# H616 register map
Vendor: Allwinner; Series: H616; File version: 0.1
CPU: other 0, little endian, MPU, no FPU, 0 interrupt priority bits
Registers are 32-bit, read-write, reset 0x0 unless marked. A register's access mark holds for its fields unless they carry their own. Offsets are from the block's base; [hi:lo] are bit positions; {n}, {i} and the like mark numbered series; 'fields as' and 'values as' point back to an identical list.

## CCU
Base 0x03001000
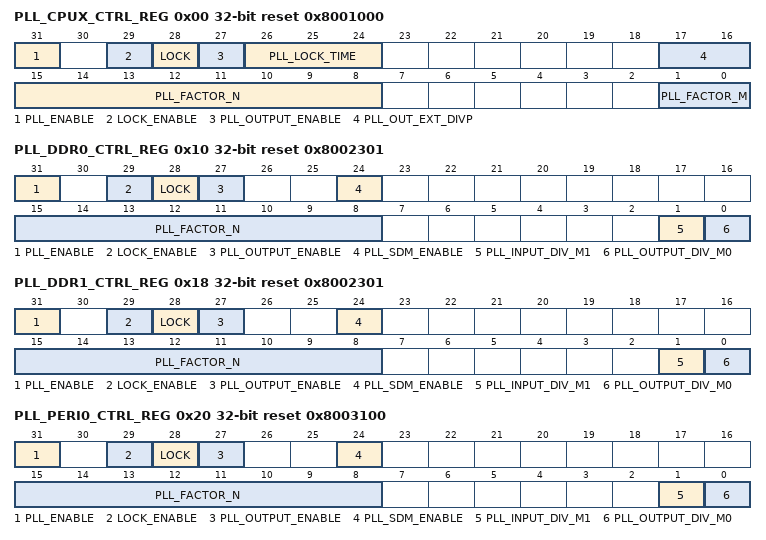
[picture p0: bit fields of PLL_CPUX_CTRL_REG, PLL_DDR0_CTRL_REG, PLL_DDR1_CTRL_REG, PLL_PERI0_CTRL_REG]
0x00 PLL_CPUX_CTRL_REG reset 0x8001000 — PLL_CPUX Control Register
  [31] PLL_ENABLE — 0: Disable 1: Enable PLL_CPUX=24 MHz*N/P The PLL_CPUX output frequency must be in the range from 200 MHz to 3 GHz. And the default value of PLL_CPUX is 408 MHz.
    0=Disable; 1=Enable PLL_CPUX=24 MHz*N/P The PLL_CPUX output frequency must be in the range from 200 MHz to 3 GHz. And the default value of PLL_CPUX is 408 MHz.
  [29] LOCK_ENABLE — Lock Enable 0: Disable 1: Enable
    0=Disable; 1=Enable
  [28] LOCK ro — 0:Unlocked 1: Locked (It indicates that the PLL has been stable.)
    1=Locked (It indicates that the PLL has been stable.)
  [27] PLL_OUTPUT_ENABLE — 0:Disable 1:Enable The bit is used to control the output enable of PLL.
  [26:24] PLL_LOCK_TIME — PLL lock time The bit indicates the step amplitude from one frequency to another.
  [17:16] PLL_OUT_EXT_DIVP — PLL Output External Divider P 00: 1 01: 2 10: 4 11: / When output clock is less than 288 MHz, clock frequency is output by dividing P.
    0=_1; 1=_2; 2=_4; 3=_slash_ (/ When output clock is less than 288 MHz, clock frequency is output by dividing P.)
  [15:8] PLL_FACTOR_N — PLL Factor N N= PLL_FACTOR_N +1 PLL_FACTOR_N is from 0 to 254. In application, PLL_FACTOR_N shall be more than or equal to 11.
  [1:0] PLL_FACTOR_M — PLL Factor M M = PLL_FACTOR_M + 1 PLL_FACTOR_M is from 0 to 3. Note: The bit is only for testing.
0x10 PLL_DDR0_CTRL_REG reset 0x8002301 — PLL_DDR0 Control Register
  [31] PLL_ENABLE — 0: Disable 1: Enable PLL_DDR= 24 MHz*N/M0/M1 The default value of PLL_DDR0 is 432 MHz.
    0=Disable; 1=Enable PLL_DDR= 24 MHz*N/M0/M1 The default value of PLL_DDR0 is 432 MHz
  [29] LOCK_ENABLE — Lock Enable 0: Disable 1: Enable
    0=Disable; 1=Enable
  [28] LOCK ro — 0: Unlocked 1: Locked (It indicates that the PLL has been stable.)
    0=Unlocked; 1=Locked (It indicates that the PLL has been stable.)
  [27] PLL_OUTPUT_ENABLE — 0:Disable 1:Enable The bit is used to control the output enable of PLL.
  [24] PLL_SDM_ENABLE — 0:Disable 1:Enable
  [15:8] PLL_FACTOR_N — PLL Factor N N= PLL_FACTOR_N +1 PLL_FACTOR_N is from 0 to 254. In application, PLL_FACTOR_N shall be more than or equal to 11.
  [1] PLL_INPUT_DIV_M1 — PLL Input Div M1. M1=PLL_INPUT_DIV_M1 + 1 PLL_INPUT_DIV_M1 is from 0 to 1.
  [0] PLL_OUTPUT_DIV_M0 — PLL Output Div M0. M0=PLL_OUTPUT_DIV_M0 + 1 PLL_OUTPUT_DIV_M0 is from 0 to 1.
0x18 PLL_DDR1_CTRL_REG reset 0x8002301 — PLL_DDR1 Control Register
  [31] PLL_ENABLE — 0: Disable 1: Enable PLL_DDR= 24 MHz*N/M0/M1 The default value of PLL_DDR1 is 432 MHz.
    0=Disable; 1=Enable PLL_DDR= 24 MHz*N/M0/M1 The default value of PLL_DDR1 is 432 MHz
  [29] LOCK_ENABLE — Lock Enable 0: Disable 1: Enable
    0=Disable; 1=Enable
  [28] LOCK ro — 0: Unlocked 1: Locked (It indicates that the PLL has been stable.)
    values as PLL_DDR0_CTRL_REG.LOCK
  [27] PLL_OUTPUT_ENABLE — 0:Disable 1:Enable The bit is used to control the output enable of PLL.
  [24] PLL_SDM_ENABLE — 0:Disable 1:Enable
  [15:8] PLL_FACTOR_N — PLL Factor N N= PLL_FACTOR_N +1 PLL_FACTOR_N is from 0 to 254. In application, PLL_FACTOR_N shall be more than or equal to 11.
  [1] PLL_INPUT_DIV_M1 — PLL Input Div M1. M1=PLL_INPUT_DIV_M1 + 1 PLL_INPUT_DIV_M1 is from 0 to 1.
  [0] PLL_OUTPUT_DIV_M0 — PLL Output Div M0. M0=PLL_OUTPUT_DIV_M0 + 1 PLL_OUTPUT_DIV_M0 is from 0 to 1.
0x20 PLL_PERI0_CTRL_REG reset 0x8003100 — PLL_PERI0 Control Register
  [31] PLL_ENABLE — 0: Disable 1: Enable PLL_PERI0(2X) = 24 MHz*N/M0/M1 PLL_PERI0(1X) = 24 MHz*N/M0/M1/2 The default value of PLL_PERI0(2X) is 1.2 GHz. It is not recommended to modify the value.
    0=Disable; 1=Enable PLL_PERI0(2X) = 24 MHz*N/M0/M1 PLL_PERI0(1X) = 24 MHz*N/M0/M1/2 The default value of PLL_PERI0(2X) is 1.2 GHz. It is not recommended to modify the value.
  [29] LOCK_ENABLE — Lock Enable 0: Disable 1: Enable
    0=Disable; 1=Enable
  [28] LOCK ro — 0: Unlocked 1: Locked (It indicates that the PLL has been stable.)
    values as PLL_DDR0_CTRL_REG.LOCK
  [27] PLL_OUTPUT_ENABLE — 0:Disable 1:Enable The bit is used to control the output enable of PLL.
  [24] PLL_SDM_ENABLE — 0: Disable 1: Enable
    0=Disable; 1=Enable
  [15:8] PLL_FACTOR_N — PLL Factor N N= PLL_FACTOR_N +1 PLL_FACTOR_N is from 0 to 254. In application, PLL_FACTOR_N shall be more than or equal to 11.
  [1] PLL_INPUT_DIV_M1 — PLL Input Div M1. M1=PLL_INPUT_DIV_M1 + 1 PLL_INPUT_DIV_M1 is from 0 to 1.
  [0] PLL_OUTPUT_DIV_M0 — PLL Output Div M0. M0=PLL_OUTPUT_DIV_M0 + 1 PLL_OUTPUT_DIV_M0 is from 0 to 1.
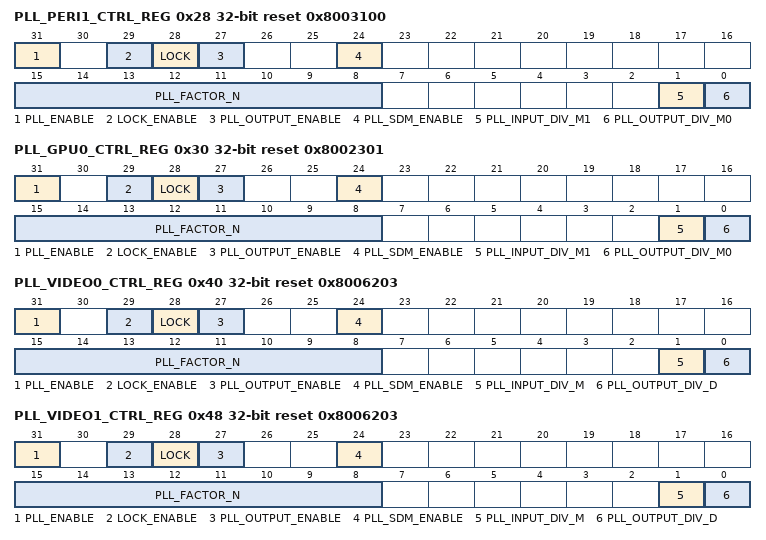
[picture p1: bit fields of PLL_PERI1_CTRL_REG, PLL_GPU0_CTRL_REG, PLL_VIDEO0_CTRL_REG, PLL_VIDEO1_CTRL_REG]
0x28 PLL_PERI1_CTRL_REG reset 0x8003100 — PLL_PERI1 Control Register
  [31] PLL_ENABLE — 0: Disable 1: Enable PLL_PERI1(2X) = 24 MHz*N/M0/M1. PLL_PERI1(1X) = 24 MHz*N/M0/M1/2. The default value of PLL_PERI1(2X) is 1.2 GHz. It is not recommended to modify the value.
    0=Disable; 1=Enable PLL_PERI1(2X) = 24 MHz*N/M0/M1. PLL_PERI1(1X) = 24 MHz*N/M0/M1/2. The default value of PLL_PERI1(2X) is 1.2 GHz. It is not recommended to modify the value.
  [29] LOCK_ENABLE — Lock Enable 0: Disable 1: Enable
    0=Disable; 1=Enable
  [28] LOCK ro — 0:Unlocked 1: Locked (It indicates that the PLL has been stable.)
    1=Locked (It indicates that the PLL has been stable.)
  [27] PLL_OUTPUT_ENABLE — 0:Disable 1:Enable The bit is used to control the output enable of PLL.
  [24] PLL_SDM_ENABLE — 0: Disable 1: Enable
    0=Disable; 1=Enable
  [15:8] PLL_FACTOR_N — PLL Factor N N= PLL_FACTOR_N +1 PLL_FACTOR_N is from 0 to 254. In application, PLL_FACTOR_N shall be more than or equal to 11.
  [1] PLL_INPUT_DIV_M1 — PLL Input Div M1 M1=PLL_INPUT_DIV_M1 + 1 PLL_INPUT_DIV_M1 is from 0 to 1.
  [0] PLL_OUTPUT_DIV_M0 — PLL Output Div M0 M0=PLL_OUTPUT_DIV_M0 + 1 PLL_OUTPUT_DIV_M0 is from 0 to 1.
0x30 PLL_GPU0_CTRL_REG reset 0x8002301 — PLL_GPU0 Control Register
  [31] PLL_ENABLE — 0: Disable 1: Enable PLL_GPU0 = 24 MHz*N/M0/M1. The default value of PLL_GPU0 is 432 MHz.
    0=Disable; 1=Enable PLL_GPU0 = 24 MHz*N/M0/M1. The default value of PLL_GPU0 is 432 MHz.
  [29] LOCK_ENABLE — Lock Enable 0: Disable 1: Enable
    0=Disable; 1=Enable
  [28] LOCK ro — 0:Unlocked 1: Locked (It indicates that the PLL has been stable.)
    1=Locked (It indicates that the PLL has been stable.)
  [27] PLL_OUTPUT_ENABLE — 0:Disable 1:Enable The bit is used to control the output enable of PLL.
  [24] PLL_SDM_ENABLE — 0: Disable 1: Enable
    0=Disable; 1=Enable
  [15:8] PLL_FACTOR_N — PLL Factor N. N= PLL_FACTOR_N +1 PLL_FACTOR_N is from 0 to 254. In application, PLL_FACTOR_N shall be more than or equal to 11.
  [1] PLL_INPUT_DIV_M1 — PLL Input Div M1. M1=PLL_INPUT_DIV_M1 + 1 PLL_INPUT_DIV_M1 is from 0 to 1.
  [0] PLL_OUTPUT_DIV_M0 — PLL Output Div M0. M0=PLL_OUTPUT_DIV_M0 + 1 PLL_OUTPUT_DIV_M0 is from 0 to 1.
0x40 PLL_VIDEO0_CTRL_REG reset 0x8006203 — PLL_VIDEO0 Control Register
  [31] PLL_ENABLE — 0: Disable 1: Enable For application, PLL_VIDEO0(4X)= 24 MHz*N/M. PLL_VIDEO0(1X)=24 MHz*N/M/4. The default value of PLL_VIDEO0(4X) is 1188 MHz.
    0=Disable; 1=Enable For application, PLL_VIDEO0(4X)= 24 MHz*N/M. PLL_VIDEO0(1X)=24 MHz*N/M/4. The default value of PLL_VIDEO0(4X) is 1188 MHz.
  [29] LOCK_ENABLE — Lock Enable 0: Disable 1: Enable
    0=Disable; 1=Enable
  [28] LOCK ro — 0:Unlocked 1: Locked (It indicates that the PLL has been stable.)
    1=Locked (It indicates that the PLL has been stable.)
  [27] PLL_OUTPUT_ENABLE — 0: Disable 1: Enable The bit is used to control the output enable of PLL.
    0=Disable; 1=Enable The bit is used to control the output enable of PLL
  [24] PLL_SDM_ENABLE — 0: Disable 1: Enable
    0=Disable; 1=Enable
  [15:8] PLL_FACTOR_N — PLL Factor N N= PLL_FACTOR_N +1 PLL_FACTOR_N is from 0 to 254. In application, PLL_FACTOR_N shall be more than or equal to 11.
  [1] PLL_INPUT_DIV_M — PLL Input Div M M1=PLL_INPUT_DIV_M + 1 PLL_INPUT_DIV_M is from 0 to 1.
  [0] PLL_OUTPUT_DIV_D — PLL Output Div D M0=PLL_OUTPUT_DIV_D + 1 PLL_OUTPUT_DIV_D is from 0 to 1. The bit is only for testing. For test, PLL_VIDEO0(4X) =24 MHz*N/M/D
0x48 PLL_VIDEO1_CTRL_REG reset 0x8006203 — PLL_VIDEO1 Control Register
  [31] PLL_ENABLE — 0: Disable 1: Enable For application, PLL_VIDEO1(4X)= 24 MHz*N/M. PLL_VIDEO1(1X)=24 MHz*N/M/4. The default value of PLL_VIDEO1(4X) is 1188 MHz.
    0=Disable; 1=Enable For application, PLL_VIDEO1(4X)= 24 MHz*N/M. PLL_VIDEO1(1X)=24 MHz*N/M/4. The default value of PLL_VIDEO1(4X) is 1188 MHz.
  [29] LOCK_ENABLE — Lock Enable 0: Disable 1: Enable
    0=Disable; 1=Enable
  [28] LOCK ro — 0: Unlocked 1: Locked (It indicates that the PLL has been stable.)
    values as PLL_DDR0_CTRL_REG.LOCK
  [27] PLL_OUTPUT_ENABLE — 0: Disable 1: Enable The bit is used to control the output enable of PLL.
    values as PLL_VIDEO0_CTRL_REG.PLL_OUTPUT_ENABLE
  [24] PLL_SDM_ENABLE — 0: Disable 1: Enable
    0=Disable; 1=Enable
  [15:8] PLL_FACTOR_N — PLL Factor N N= PLL_FACTOR_N +1 PLL_FACTOR_N is from 0 to 254. In application, PLL_FACTOR_N shall be more than or equal to 11.
  [1] PLL_INPUT_DIV_M — PLL Input Div M M1=PLL_INPUT_DIV_M + 1 PLL_INPUT_DIV_M is from 0 to 1.
  [0] PLL_OUTPUT_DIV_D — PLL Output Div D M0=PLL_OUTPUT_DIV_D + 1 PLL_OUTPUT_DIV_D is from 0 to 1. The bit is only for testing. For test, PLL_VIDEO0(4X) =24 MHz*N/M/D
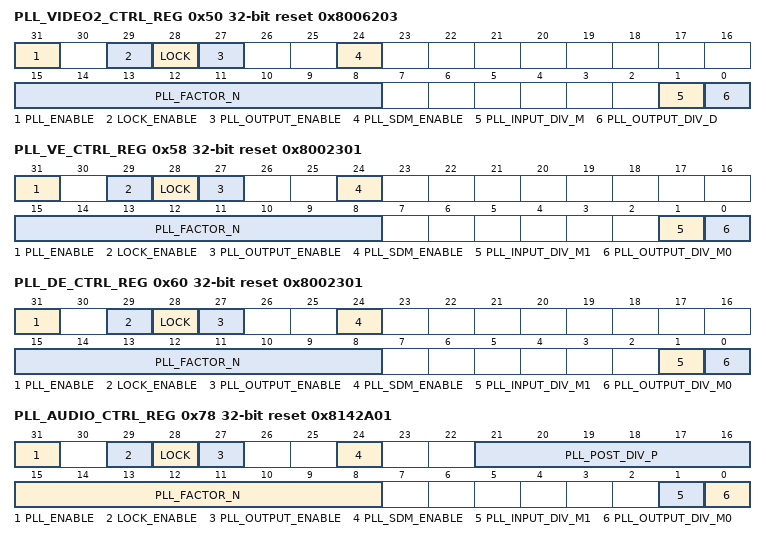
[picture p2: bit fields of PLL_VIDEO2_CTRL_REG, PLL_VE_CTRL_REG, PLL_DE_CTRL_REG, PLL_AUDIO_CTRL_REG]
0x50 PLL_VIDEO2_CTRL_REG reset 0x8006203
  [31] PLL_ENABLE — 0: Disable 1: Enable For application, PLL_VIDEO2(4X)= 24 MHz*N/M. PLL_VIDEO2(1X)=24 MHz*N/M/4. The default value of PLL_VIDEO2(4X) is 1188 MHz.
    0=Disable; 1=Enable For application, PLL_VIDEO2(4X)= 24 MHz*N/M. PLL_VIDEO2(1X)=24 MHz*N/M/4. The default value of PLL_VIDEO2(4X) is 1188 MHz.
  [29] LOCK_ENABLE — Lock Enable 0: Disable 1: Enable
    0=Disable; 1=Enable
  [28] LOCK ro — 0:Unlocked 1: Locked (It indicates that the PLL has been stable.)
    1=Locked (It indicates that the PLL has been stable.)
  [27] PLL_OUTPUT_ENABLE — 0: Disable 1: Enable The bit is used to control the output enable of PLL.
    values as PLL_VIDEO0_CTRL_REG.PLL_OUTPUT_ENABLE
  [24] PLL_SDM_ENABLE — 0: Disable 1: Enable
    0=Disable; 1=Enable
  [15:8] PLL_FACTOR_N — PLL Factor N N= PLL_FACTOR_N +1 PLL_FACTOR_N is from 0 to 254. In application, PLL_FACTOR_N shall be more than or equal to 11.
  [1] PLL_INPUT_DIV_M — PLL Input Div M M1=PLL_INPUT_DIV_M + 1 PLL_INPUT_DIV_M is from 0 to 1.
  [0] PLL_OUTPUT_DIV_D — PLL Output Div D M0=PLL_OUTPUT_DIV_D + 1 PLL_OUTPUT_DIV_D is from 0 to 1. The bit is only for testing. For test, PLL_VIDEO0(4X) =24 MHz*N/M/D
0x58 PLL_VE_CTRL_REG reset 0x8002301 — PLL_VE Control Register
  [31] PLL_ENABLE — 0: Disable 1: Enable The PLL_VE = 24 MHz*N/M0/M1. The default value of PLL_VE is 432 MHz.
    0=Disable; 1=Enable The PLL_VE = 24 MHz*N/M0/M1. The default value of PLL_VE is 432 MHz.
  [29] LOCK_ENABLE — Lock Enable 0: Disable 1: Enable
    0=Disable; 1=Enable
  [28] LOCK ro — 0:Unlocked 1: Locked (It indicates that the PLL has been stable.)
    1=Locked (It indicates that the PLL has been stable.)
  [27] PLL_OUTPUT_ENABLE — 0: Disable 1: Enable The bit is used to control the output enable of PLL.
    values as PLL_VIDEO0_CTRL_REG.PLL_OUTPUT_ENABLE
  [24] PLL_SDM_ENABLE — 0: Disable 1: Enable
    0=Disable; 1=Enable
  [15:8] PLL_FACTOR_N — PLL Factor N. N= PLL_FACTOR_N +1 PLL_FACTOR_N is from 0 to 254. In application, PLL_FACTOR_N shall be more than or equal to 11.
  [1] PLL_INPUT_DIV_M1 — PLL Input Div M1. M1=PLL_INPUT_DIV_M1 + 1 PLL_INPUT_DIV_M1 is from 0 to 1.
  [0] PLL_OUTPUT_DIV_M0 — PLL Output Div M0. M0=PLL_OUTPUT_DIV_M0 + 1 PLL_OUTPUT_DIV_M0 is from 0 to 1.
0x60 PLL_DE_CTRL_REG reset 0x8002301 — PLL_DE Control Register
  [31] PLL_ENABLE — 0: Disable 1: Enable PLL_DE = 24 MHz*N/M0/M1. The default value of PLL_DE is 432 MHz.
    0=Disable; 1=Enable PLL_DE = 24 MHz*N/M0/M1. The default value of PLL_DE is 432 MHz.
  [29] LOCK_ENABLE — Lock Enable 0: Disable 1: Enable
    0=Disable; 1=Enable
  [28] LOCK ro — 0: Unlocked 1: Locked (It indicates that the PLL has been stable.)
    values as PLL_DDR0_CTRL_REG.LOCK
  [27] PLL_OUTPUT_ENABLE — 0: Disable 1: Enable The bit is used to control the output enable of PLL.
    values as PLL_VIDEO0_CTRL_REG.PLL_OUTPUT_ENABLE
  [24] PLL_SDM_ENABLE — 0: Disable 1: Enable
    0=Disable; 1=Enable
  [15:8] PLL_FACTOR_N — PLL Factor N N= PLL_FACTOR_N +1 PLL_FACTOR_N is from 0 to 254. In application, PLL_FACTOR_N shall be more than or equal to 11.
  [1] PLL_INPUT_DIV_M1 — PLL Input Div M1. M1=PLL_INPUT_DIV_M1 + 1 PLL_INPUT_DIV_M1 is from 0 to 1.
  [0] PLL_OUTPUT_DIV_M0 — PLL Output Div M0. M0=PLL_OUTPUT_DIV_M0 + 1 PLL_OUTPUT_DIV_M0 is from 0 to 1.
0x78 PLL_AUDIO_CTRL_REG reset 0x8142A01 — PLL_AUDIO Control Register
  [31] PLL_ENABLE — 0: Disable 1: Enable This PLL is for Audio. PLL_AUDIO(hs)=24 MHz*N/M1 PLL_AUDIO(4X) = 24 MHz*N/M0/M1/P PLL_AUDIO(2X) = 24 MHz*N/M0/M1/P/2 PLL_AUDIO(1X) = 24 MHz*N/M0/M1/P/4 7.5<=N/M0/M1<=125 and 12<=N The range of 24 MHz*N/M0/M1 is from 180 MHz to 3 GHz. The default value of PLL_AUDIO(4X) is 24.5714 MHz. Common configuration: When PLL_AUDIO(1X) is 24.576 MHz, PLL_AUDIO_CTRL_REG is recommended to set to 0xA8010F01, PLL_AUDIO_PAR0_CTRL_REG is recommended to set to 0xE000C49B. When PLL_AUDIO(1X) is 22.5792 MHz, PLL_AUDIO_CTRL_REG is recommended to set to 0xA8021501, PLL_AUDIO_PAR0_CTRL_REG is recommended to set to 0xE001288C.
    0=Disable; 1=Enable This PLL is for Audio. PLL_AUDIO(hs)=24 MHz*N/M1 PLL_AUDIO(4X) = 24 MHz*N/M0/M1/P PLL_AUDIO(2X) = 24 MHz*N/M0/M1/P/2 PLL_AUDIO(1X) = 24 MHz*N/M0/M1/P/4 7.5<=N/M0/M1<=125 and 12<=N The range of 24 MHz*N/M0/M1 is from 180 MHz to 3 GHz. The default value of PLL_AUDIO(4X) is 24.5714 MHz. Common configuration: When PLL_AUDIO(1X) is 24.576 MHz, PLL_AUDIO_CTRL_REG is recommended to set to 0xA8010F01, PLL_AUDIO_PAR0_CTRL_REG is recommended to set to 0xE000C49B. When PLL_AUDIO(1X) is 22.5792 MHz, PLL_AUDIO_CTRL_REG is recommended to set to 0xA8021501, PLL_AUDIO_PAR0_CTRL_REG is recommended to set to 0xE001288C.
  [29] LOCK_ENABLE — Lock Enable 0: Disable 1: Enable
    0=Disable; 1=Enable
  [28] LOCK ro — 0:Unlocked 1: Locked (It indicates that the PLL has been stable.) Note: The bit is only valid when the bit29 is set to 1.
    1=Locked (It indicates that the PLL has been stable.) Note: The bit is only valid when the bit29 is set to 1
  [27] PLL_OUTPUT_ENABLE — 0:Disable 1:Enable The bit is used to control the output enable of PLL.
  [24] PLL_SDM_ENABLE — Spread Spectrum and Decimal Frequency Division 0: Disable 1: Enable
    0=Disable; 1=Enable
  [21:16] PLL_POST_DIV_P — PLL Post-div P P= PLL_POST_DIV_P +1 PLL_POST_DIV_P is from 0 to 63.
  [15:8] PLL_FACTOR_N — PLL Factor N N= PLL_FACTOR_N +1 PLL_FACTOR_N is from 0 to 254. In application, PLL_FACTOR_N shall be more than or equal to 11.
  [1] PLL_INPUT_DIV_M1 — PLL Input Div M1 M1=PLL_INPUT_DIV_M1 + 1 PLL_INPUT_DIV_M1 is from 0 to 1.
  [0] PLL_OUTPUT_DIV_M0 — PLL Output Div M0 M0=PLL_OUTPUT_DIV_M0 + 1 PLL_OUTPUT_DIV_M0 is from 0 to 1.
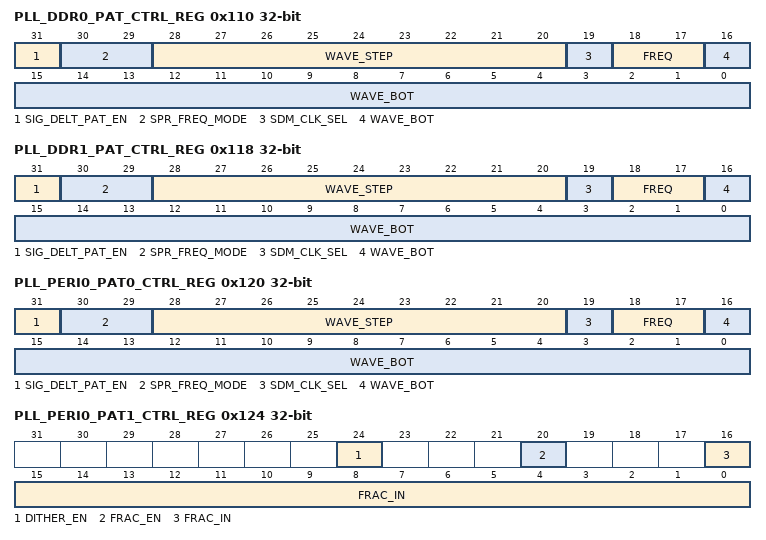
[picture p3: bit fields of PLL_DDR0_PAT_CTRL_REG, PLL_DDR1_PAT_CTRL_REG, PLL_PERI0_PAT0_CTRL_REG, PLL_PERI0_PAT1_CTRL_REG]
0x110 PLL_DDR0_PAT_CTRL_REG — PLL_DDR0 Pattern Control Register
  [31] SIG_DELT_PAT_EN — Sigma-Delta Pattern Enable
  [30:29] SPR_FREQ_MODE — Spread Frequency Mode 00: DC=0 01: DC=1 10: Triangular(1bit) 11: Triangular(nbit)
    0=DC_equals_0 (DC=0); 1=DC_equals_1 (DC=1); 2=Triangular_openingparen_1bit_closingparen_ (Triangular(1bit)); 3=Triangular_openingparen_nbit_closingparen_ (Triangular(nbit))
  [28:20] WAVE_STEP
  [19] SDM_CLK_SEL — SDM Clock Select 0: 24 MHz 1: 12 MHz When PLL_INPUT_DIV_M1 is 1, the bit is set to 1.
    0=24 MHz; 1=12 MHz When PLL_INPUT_DIV_M1 is 1, the bit is set to 1
  [18:17] FREQ — Frequency 00: 31.5 kHz 01: 32 kHz 10: 32.5 kHz 11: 33 kHz
    0=_31_point_5_kHz (31.5 kHz); 1=_32_kHz; 2=_32_point_5_kHz (32.5 kHz); 3=_33_kHz
  [16:0] WAVE_BOT — Wave Bottom
0x118 PLL_DDR1_PAT_CTRL_REG — PLL_DDR1 Pattern Control Register
  fields as PLL_DDR0_PAT_CTRL_REG
0x120 PLL_PERI0_PAT0_CTRL_REG — PLL_PERI0 Pattern0 Control Register
  [31] SIG_DELT_PAT_EN — Sigma-Delta Pattern Enable
  [30:29] SPR_FREQ_MODE — Spread Frequency Mode 00: DC=0 01: DC=1 10: Triangular(1bit) 11: Triangular(nbit)
    values as PLL_DDR0_PAT_CTRL_REG.SPR_FREQ_MODE
  [28:20] WAVE_STEP
  [19] SDM_CLK_SEL — SDM Clock Select 0: 24 MHz 1: 12 MHz Note: When PLL_INPUT_DIV_M1 is 1, the bit is set to 1.
    0=24 MHz; 1=12 MHz Note: When PLL_INPUT_DIV_M1 is 1, the bit is set to 1
  [18:17] FREQ — Frequency 00: 31.5 kHz 01: 32 kHz 10: 32.5 kHz 11: 33 kHz
    values as PLL_DDR0_PAT_CTRL_REG.FREQ
  [16:0] WAVE_BOT — Wave Bottom
0x124 PLL_PERI0_PAT1_CTRL_REG — PLL_PERI0 Pattern1 Control Register
  [24] DITHER_EN, [20] FRAC_EN, [16:0] FRAC_IN
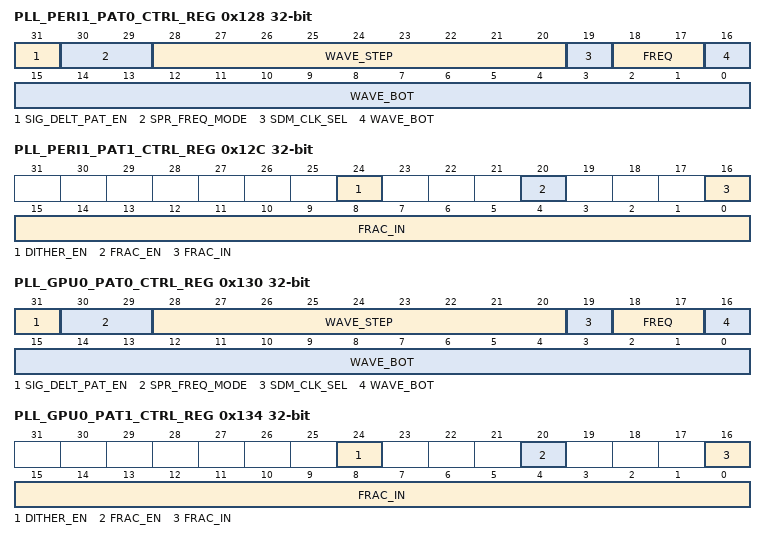
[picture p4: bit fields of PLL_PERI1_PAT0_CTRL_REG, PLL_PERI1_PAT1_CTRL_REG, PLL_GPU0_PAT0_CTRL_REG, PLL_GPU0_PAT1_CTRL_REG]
0x128 PLL_PERI1_PAT0_CTRL_REG — PLL_PERI1 Pattern0 Control Register
  [31] SIG_DELT_PAT_EN — Sigma-Delta Pattern Enable
  [30:29] SPR_FREQ_MODE — Spread Frequency Mode 00: DC=0 01: DC=1 10: Triangular(1 bit) 11: Triangular(n bit)
    0=DC_equals_0 (DC=0); 1=DC_equals_1 (DC=1); 2=Triangular_openingparen_1 (Triangular(1 bit)); 3=Triangular_openingparen_n (Triangular(n bit))
  [28:20] WAVE_STEP
  [19] SDM_CLK_SEL — SDM Clock Select 0: 24 MHz 1: 12 MHz Note: When PLL_INPUT_DIV_M1 is 1, the bit is set to 1.
    values as PLL_PERI0_PAT0_CTRL_REG.SDM_CLK_SEL
  [18:17] FREQ — Frequency 00: 31.5 kHz 01: 32 kHz 10: 32.5 kHz 11: 33 kHz
    values as PLL_DDR0_PAT_CTRL_REG.FREQ
  [16:0] WAVE_BOT — Wave Bottom
0x12C PLL_PERI1_PAT1_CTRL_REG — PLL_PERI1 Pattern1 Control Register
  [24] DITHER_EN, [20] FRAC_EN, [16:0] FRAC_IN
0x130 PLL_GPU0_PAT0_CTRL_REG — PLL_GPU0 Pattern0 Control Register
  fields as PLL_PERI1_PAT0_CTRL_REG
0x134 PLL_GPU0_PAT1_CTRL_REG — PLL_GPU0 Pattern1 Control Register
  [24] DITHER_EN, [20] FRAC_EN, [16:0] FRAC_IN
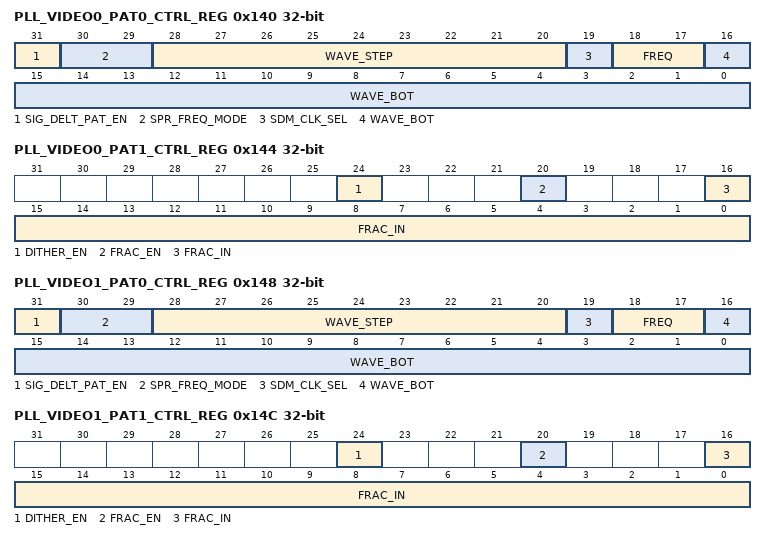
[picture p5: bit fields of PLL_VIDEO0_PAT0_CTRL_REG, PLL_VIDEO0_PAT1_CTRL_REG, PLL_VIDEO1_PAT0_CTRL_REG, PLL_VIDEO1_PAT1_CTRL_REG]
0x140 PLL_VIDEO0_PAT0_CTRL_REG — PLL_VIDEO0 Pattern0 Control Register
  fields as PLL_PERI1_PAT0_CTRL_REG
0x144 PLL_VIDEO0_PAT1_CTRL_REG — PLL_VIDEO0 Pattern1 Control Register
  [24] DITHER_EN, [20] FRAC_EN, [16:0] FRAC_IN
0x148 PLL_VIDEO1_PAT0_CTRL_REG — PLL_VIDEO1 Pattern0 Control Register
  fields as PLL_PERI1_PAT0_CTRL_REG
0x14C PLL_VIDEO1_PAT1_CTRL_REG — PLL_VIDEO1 Pattern1 Control Register
  [24] DITHER_EN, [20] FRAC_EN, [16:0] FRAC_IN
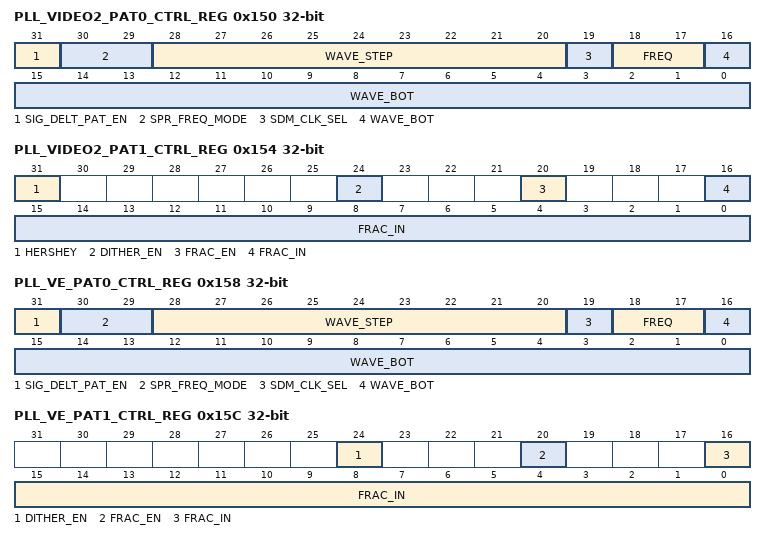
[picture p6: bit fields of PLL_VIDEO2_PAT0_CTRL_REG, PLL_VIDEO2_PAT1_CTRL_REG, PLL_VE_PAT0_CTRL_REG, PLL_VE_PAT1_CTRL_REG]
0x150 PLL_VIDEO2_PAT0_CTRL_REG
  fields as PLL_PERI1_PAT0_CTRL_REG
0x154 PLL_VIDEO2_PAT1_CTRL_REG
  [31] HERSHEY — EN 0: triangular 1: hershey
    0=triangular; 1=hershey
  [24] DITHER_EN
  [20] FRAC_EN
  [16:0] FRAC_IN
0x158 PLL_VE_PAT0_CTRL_REG — PLL_VE Pattern0 Control Register
  fields as PLL_PERI1_PAT0_CTRL_REG
0x15C PLL_VE_PAT1_CTRL_REG — PLL_VE Pattern1 Control Register
  [24] DITHER_EN, [20] FRAC_EN, [16:0] FRAC_IN
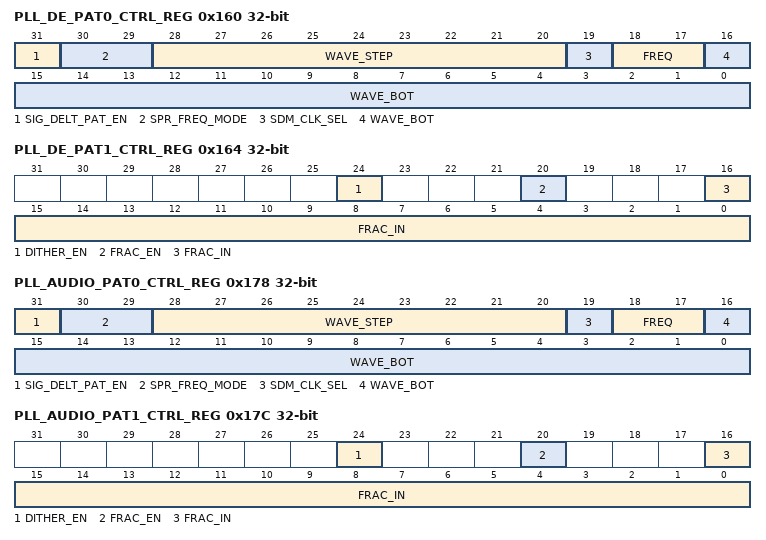
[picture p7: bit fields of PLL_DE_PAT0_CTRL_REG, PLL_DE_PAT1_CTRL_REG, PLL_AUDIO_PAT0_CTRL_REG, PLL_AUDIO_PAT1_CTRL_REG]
0x160 PLL_DE_PAT0_CTRL_REG — PLL_DE Pattern0 Control Register
  fields as PLL_PERI1_PAT0_CTRL_REG
0x164 PLL_DE_PAT1_CTRL_REG — PLL_DE Pattern1 Control Register
  [24] DITHER_EN, [20] FRAC_EN, [16:0] FRAC_IN
0x178 PLL_AUDIO_PAT0_CTRL_REG — PLL_AUDIO Pattern0 Control Register
  fields as PLL_PERI1_PAT0_CTRL_REG
0x17C PLL_AUDIO_PAT1_CTRL_REG — PLL_AUDIO Pattern1 Control Register
  [24] DITHER_EN, [20] FRAC_EN, [16:0] FRAC_IN
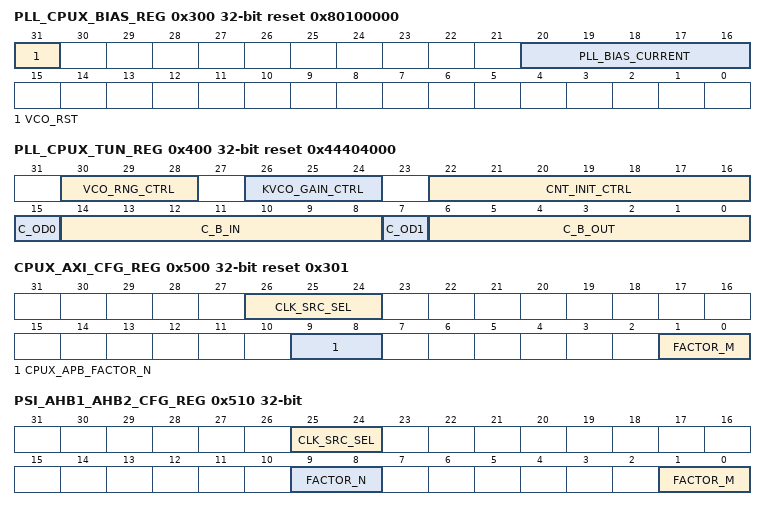
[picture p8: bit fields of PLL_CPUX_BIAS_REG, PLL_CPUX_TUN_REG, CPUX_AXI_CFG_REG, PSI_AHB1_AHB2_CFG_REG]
0x300 PLL_CPUX_BIAS_REG reset 0x80100000 — PLL_CPUX Bias Register
  [31] VCO_RST — VCO reset in
  [20:16] PLL_BIAS_CURRENT — PLL current bias control [4:0], CPU_CP.
0x310 PLL_DDR0_BIAS_REG reset 0x30000 — PLL_DDR0 Bias Register
  [20:16] PLL_BIAS_CTRL — PLL bias control [4:0].
0x320 PLL_PERI0_BIAS_REG reset 0x30000 — PLL_PERI0 Bias Register
  [20:16] PLL_BIAS_CTRL — PLL bias control [4:0]
0x328 PLL_PERI1_BIAS_REG reset 0x30000 — PLL_PERI1 Bias Register
  [20:16] PLL_BIAS_CTRL — PLL bias control [4:0]
0x330 PLL_GPU0_BIAS_REG reset 0x30000 — PLL_GPU0 Bias Register
  [20:16] PLL_BIAS_CTRL — PLL bias control [4:0]
0x340 PLL_VIDEO0_BIAS_REG reset 0x30000 — PLL_VIDEO0 Bias Register
  [20:16] PLL_BIAS_CTRL — PLL bias control [4:0]
0x348 PLL_VIDEO1_BIAS_REG reset 0x30000 — PLL_VIDEO1 Bias Register
  [20:16] PLL_BIAS_CTRL — PLL bias control [4:0]
0x350 PLL_VIDEO2_BIAS_REG reset 0x30000
  [20:16] PLL_BIAS_CTRL — PLL bias control [4:0]
0x358 PLL_VE_BIAS_REG reset 0x30000 — PLL_VE Bias Register
  [20:16] PLL_BIAS_CTRL — PLL bias control [4:0]
0x360 PLL_DE_BIAS_REG reset 0x30000 — PLL_DE Bias Register
  [20:16] PLL_BIAS_CTRL — PLL bias control [4:0]
0x378 PLL_AUDIO_BIAS_REG reset 0x30000 — PLL_AUDIO Bias Register
  [20:16] PLL_BIAS_CTRL — PLL bias control [4:0]
0x400 PLL_CPUX_TUN_REG reset 0x44404000 — PLL_CPUX Tuning Register
  [30:28] VCO_RNG_CTRL — VCO range control [2:0]
  [26:24] KVCO_GAIN_CTRL — KVCO gain control [2:0]
  [22:16] CNT_INIT_CTRL — Counter initial control [6:0]
  [15] C_OD0 — C-REG-OD0 for verify
  [14:8] C_B_IN — C-B-IN [6:0] for verify
  [7] C_OD1 — C-REG-OD1 for verify
  [6:0] C_B_OUT ro — C-B-OUT [6:0] for verify
0x500 CPUX_AXI_CFG_REG reset 0x301 — CPUX_AXI Configuration Register
  [26:24] CLK_SRC_SEL — Clock Source Select 000: OSC24M 001: RTC_32K 010: RC16M 011: PLL_CPUX 100: PLL_PERI0(1X) 101: reserved 110: reserved 111: reserved CPUX Clock = Clock Source CPUX_AXI Clock = Clock Source/M CPUX_APB Clock = Clock Source/N
    0=OSC24M; 1=RTC_32K; 2=RC16M; 3=PLL_CPUX; 4=PLL_PERI0_openingparen_1X_closingparen_ (PLL_PERI0(1X))
  [9:8] CPUX_APB_FACTOR_N — Factor N.(N = FACTOR_N +1) FACTOR_N is from 0 to 3.
  [1:0] FACTOR_M — Factor M.(M = FACTOR_M +1) FACTOR_M is from 0 to 3.
0x510 PSI_AHB1_AHB2_CFG_REG — PSI_AHB1_AHB2 Configuration Register
  [25:24] CLK_SRC_SEL — Clock Source Select 00: OSC24M 01: RTC_32K 10: RC16M 11: PLL_PERI0(1X) PSI_AHB1_AHB2 CLK = Clock Source/M/N.
    0=OSC24M; 1=RTC_32K; 2=RC16M; 3=PLL_PERI0_openingparen_1X_closingparen_ (PLL_PERI0(1X) PSI_AHB1_AHB2 CLK = Clock Source/M/N.)
  [9:8] FACTOR_N — Factor N 00: 1 01: 2 10: 4 11: 8
    0=_1; 1=_2; 2=_4; 3=_8
  [1:0] FACTOR_M — Factor M.(M = FACTOR_M +1) FACTOR_M is from 0 to 3.
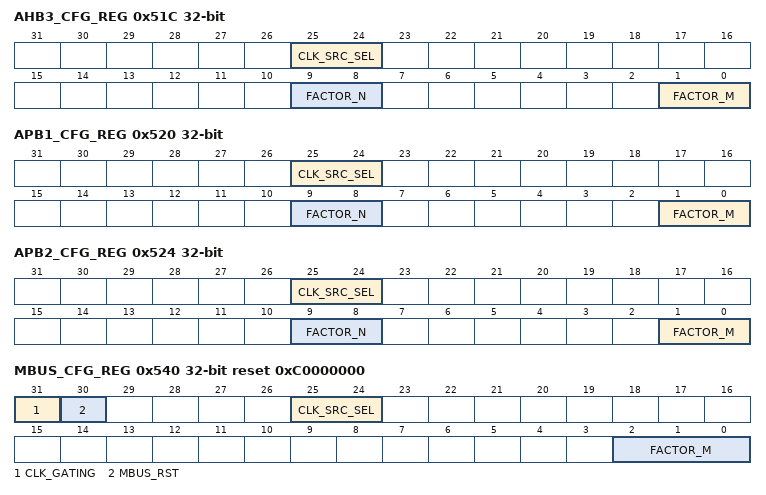
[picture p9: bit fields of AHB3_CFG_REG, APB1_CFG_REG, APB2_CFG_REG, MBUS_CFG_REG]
0x51C AHB3_CFG_REG — AHB3 Configuration Register
  [25:24] CLK_SRC_SEL — Clock Source Select 00: OSC24M 01: RTC_32K 10: PSI 11: PLL_PERI0(1X) AHB3 CLK = Clock Source/M/N.
    0=OSC24M; 1=RTC_32K; 2=PSI; 3=PLL_PERI0_openingparen_1X_closingparen_ (PLL_PERI0(1X) AHB3 CLK = Clock Source/M/N.)
  [9:8] FACTOR_N — Factor N 00: 1 01: 2 10: 4 11: 8
    0=_1; 1=_2; 2=_4; 3=_8
  [1:0] FACTOR_M — Factor M.(M = FACTOR_M +1) FACTOR_M is from 0 to 3.
0x520 APB1_CFG_REG — APB1 Configuration Register
  [25:24] CLK_SRC_SEL — Clock Source Select 00: OSC24M 01: RTC_32K 10: PSI 11: PLL_PERI0(1X) APB1 CLK = Clock Source/M/N.
    0=OSC24M; 1=RTC_32K; 2=PSI; 3=PLL_PERI0_openingparen_1X_closingparen_ (PLL_PERI0(1X) APB1 CLK = Clock Source/M/N.)
  [9:8] FACTOR_N — Factor N 00: 1 01: 2 10: 4 11: 8
    0=_1; 1=_2; 2=_4; 3=_8
  [1:0] FACTOR_M — Factor M.(M = FACTOR_M +1) FACTOR_M is from 0 to 3.
0x524 APB2_CFG_REG — APB2 Configuration Register
  [25:24] CLK_SRC_SEL — Clock Source Select 00: OSC24M 01: RTC_32K 10: PSI 11: PLL_PERI0(1X) APB2 CLK = Clock Source/M/N.
    0=OSC24M; 1=RTC_32K; 2=PSI; 3=PLL_PERI0_openingparen_1X_closingparen_ (PLL_PERI0(1X) APB2 CLK = Clock Source/M/N.)
  [9:8] FACTOR_N — Factor N 00: 1 01: 2 10: 4 11: 8
    0=_1; 1=_2; 2=_4; 3=_8
  [1:0] FACTOR_M — Factor M.(M = FACTOR_M +1) FACTOR_M is from 0 to 3.
0x540 MBUS_CFG_REG reset 0xC0000000 — MBUS Configuration Register
  [31] CLK_GATING — Gating Special Clock 0: Clock is OFF 1: Clock is ON MBUS CLK = Clock Source/M.
    0=OFF (Clock is OFF); 1=ON (Clock is ON MBUS CLK = Clock Source/M.)
  [30] MBUS_RST — MBUS Reset 0: Assert 1: De-assert
    0=Assert; 1=deassert
  [25:24] CLK_SRC_SEL — Clock Source Select 00: OSC24M 01: PLL_PERI0(2X) 10: PLL_DDR0 11: PLL_DDR1
    0=OSC24M; 1=PLL_PERI0_openingparen_2X_closingparen_ (PLL_PERI0(2X)); 2=PLL_DDR0; 3=PLL_DDR1
  [2:0] FACTOR_M — Factor M.(M = FACTOR_M +1) FACTOR_M is from 0 to 7.
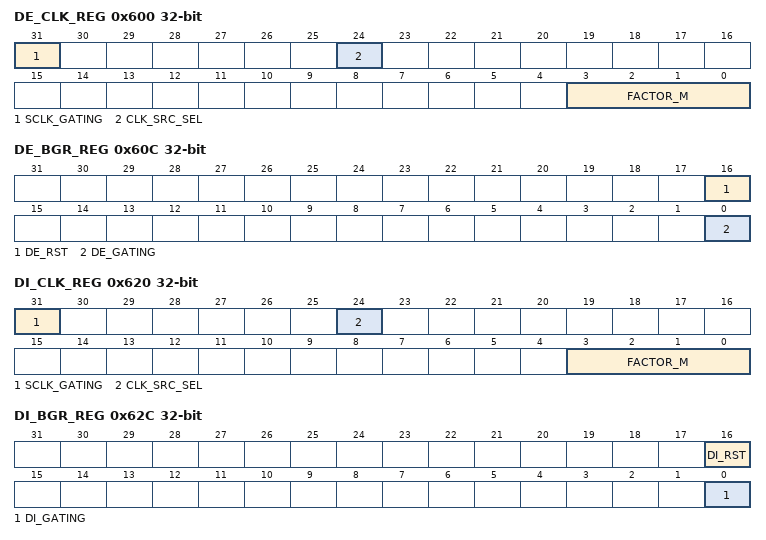
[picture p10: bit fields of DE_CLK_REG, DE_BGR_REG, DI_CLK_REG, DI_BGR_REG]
0x600 DE_CLK_REG — DE Clock Register
  [31] SCLK_GATING — Gating Special Clock 0: Clock is OFF 1: Clock is ON SCLK = Clock Source/M.
    0=OFF (Clock is OFF); 1=ON (Clock is ON SCLK = Clock Source/M.)
  [24] CLK_SRC_SEL — Clock Source Select 0: PLL_DE 1: PLL_PERI0(2X)
    0=PLL_DE; 1=PLL_PERI0_openingparen_2X_closingparen_ (PLL_PERI0(2X))
  [3:0] FACTOR_M — Factor M.(M = FACTOR_M +1) FACTOR_M is from 0 to 15.
0x60C DE_BGR_REG — DE Bus Gating Reset Register
  [16] DE_RST — DE Reset 0: Assert 1: De-assert
    0=Assert; 1=deassert
  [0] DE_GATING — Gating Clock For DE 0: Mask 1: Pass
    0=Mask; 1=Pass
0x620 DI_CLK_REG — DI Clock Register
  fields as DE_CLK_REG
0x62C DI_BGR_REG — DI Bus Gating Reset Register
  [16] DI_RST — DI Reset 0: Assert 1: De-assert
    0=Assert; 1=deassert
  [0] DI_GATING — Gating Clock For DI 0: Mask 1: Pass
    0=Mask; 1=Pass
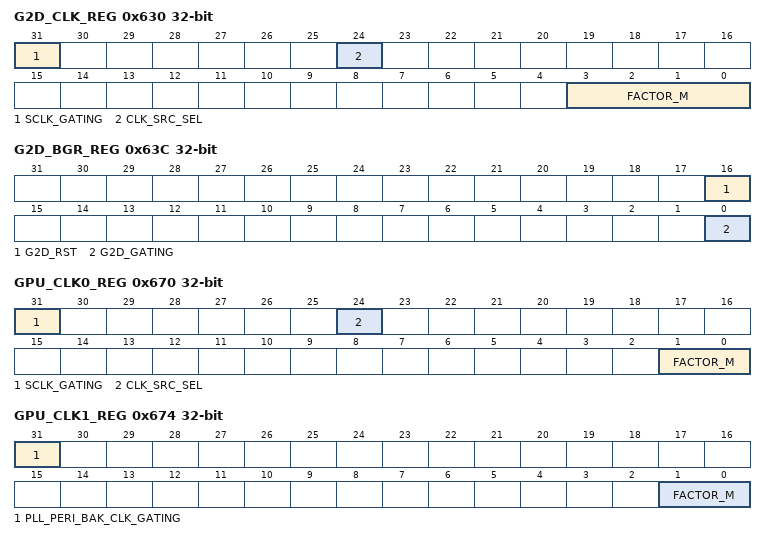
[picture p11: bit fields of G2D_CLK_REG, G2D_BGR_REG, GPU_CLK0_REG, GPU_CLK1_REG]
0x630 G2D_CLK_REG — G2D Clock Register
  fields as DE_CLK_REG
0x63C G2D_BGR_REG — G2D Bus Gating Reset Register
  [16] G2D_RST — G2D Reset 0: Assert 1: De-assert
    0=Assert; 1=deassert
  [0] G2D_GATING — Gating Clock For G2D 0: Mask 1: Pass
    0=Mask; 1=Pass
0x670 GPU_CLK0_REG
  [31] SCLK_GATING — Gating Special Clock 0: Clock is OFF 1: Clock is ON SCLK = Clock Source/M.
    values as DE_CLK_REG.SCLK_GATING
  [24] CLK_SRC_SEL — Clock Source Select 0: PLL_GPU0 1: PLL_PERI_BAK_CLK(PLL_PERI_BAK_CLK is from GPU_CLK1_REG) Note: The switch needs to be a burr-free switch.
    0=PLL_GPU0; 1=PLL_PERI_BAK_CLK_openingparen_PLL_PERI_BAK_CLK (PLL_PERI_BAK_CLK(PLL_PERI_BAK_CLK is from GPU_CLK1_REG) Note: The switch needs to be a burr-free switch.)
  [1:0] FACTOR_M — Factor M.(M= FACTOR_M +1) FACTOR_M is from 0 to 3. Burr-free divider.
0x674 GPU_CLK1_REG — GPU Clock1 Register
  [31] PLL_PERI_BAK_CLK_GATING — Gating Special Clock 0: Clock is OFF 1: Clock is ON PLL_PERI_BAK = Clock Source/M. Clock Source is from PLL_PERI0(2X). Burr-free divider.
    0=OFF (Clock is OFF); 1=ON (Clock is ON PLL_PERI_BAK = Clock Source/M. Clock Source is from PLL_PERI0(2X). Burr-free divider.)
  [1:0] FACTOR_M — Factor M.(M= FACTOR_M +1) FACTOR_M is from 0 to 3. Burr-free divider.
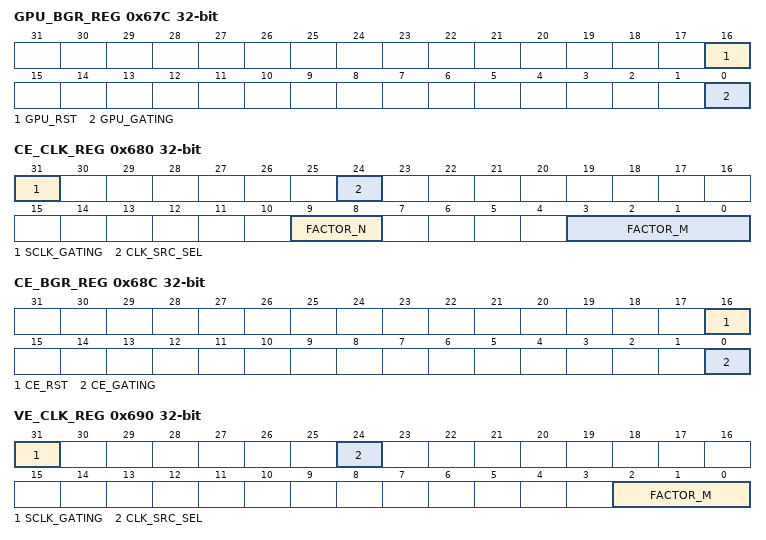
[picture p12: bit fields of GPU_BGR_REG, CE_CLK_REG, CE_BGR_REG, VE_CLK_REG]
0x67C GPU_BGR_REG — GPU Bus Gating Reset Register
  [16] GPU_RST — GPU Reset. 0: Assert 1: De-assert
    0=Assert; 1=deassert
  [0] GPU_GATING — Gating Clock For GPU 0: Mask 1: Pass
    0=Mask; 1=Pass
0x680 CE_CLK_REG — CE Clock Register
  [31] SCLK_GATING — Gating Special Clock 0: Clock is OFF 1: Clock is ON SCLK = Clock Source/M/N.
    0=OFF (Clock is OFF); 1=ON (Clock is ON SCLK = Clock Source/M/N.)
  [24] CLK_SRC_SEL — Clock Source Select 0: OSC24M 1: PLL_PERI0(2X)
    0=OSC24M; 1=PLL_PERI0_openingparen_2X_closingparen_ (PLL_PERI0(2X))
  [9:8] FACTOR_N — Factor N 00: 1 01: 2 10: 4 11: 8
    0=_1; 1=_2; 2=_4; 3=_8
  [3:0] FACTOR_M — Factor M.(M= FACTOR_M +1) FACTOR_M is from 0 to 15.
0x68C CE_BGR_REG — CE Bus Gating Reset Register
  [16] CE_RST — CE Reset 0: Assert 1: De-assert
    0=Assert; 1=deassert
  [0] CE_GATING — Gating Clock for CE 0: Mask 1: Pass
    0=Mask; 1=Pass
0x690 VE_CLK_REG — VE Clock Register
  [31] SCLK_GATING — Gating Special Clock 0: Clock is OFF 1: Clock is ON SCLK = Clock Source/Divider M.
    0=OFF (Clock is OFF); 1=ON (Clock is ON SCLK = Clock Source/Divider M.)
  [24] CLK_SRC_SEL — Clock Source Select 0: PLL_VE 1: /
    0=PLL_VE
  [2:0] FACTOR_M — Factor M.(M= FACTOR_M +1) FACTOR_M is from 0 to 7.
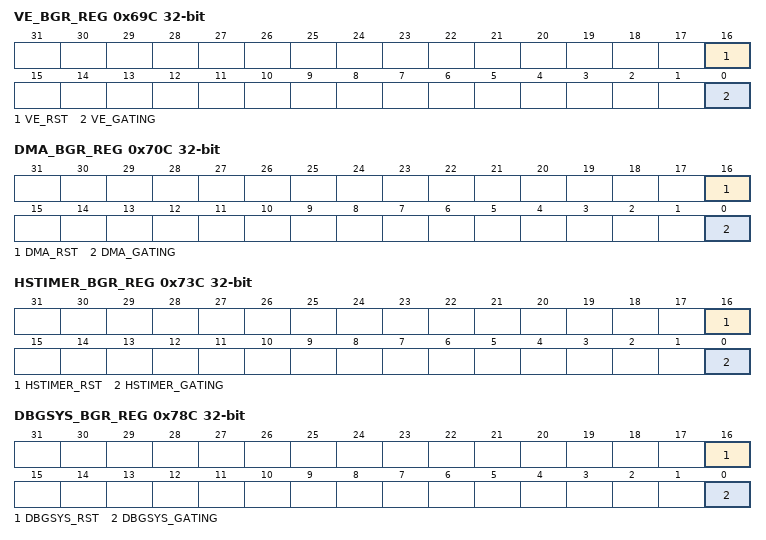
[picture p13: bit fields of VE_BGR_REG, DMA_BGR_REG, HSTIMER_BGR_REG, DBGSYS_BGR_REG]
0x69C VE_BGR_REG — VE Bus Gating Reset Register
  [16] VE_RST — VE Reset 0: Assert 1: De-assert
    0=Assert; 1=deassert
  [0] VE_GATING — Gating Clock for VE 0: Mask 1: Pass
    0=Mask; 1=Pass
0x70C DMA_BGR_REG — DMA Bus Gating Reset Register
  [16] DMA_RST — DMA Reset 0: Assert 1: De-assert
    0=Assert; 1=deassert
  [0] DMA_GATING — Gating Clock for DMA 0: Mask 1: Pass Note: The working clock of DMA is from AHB1.
    0=Mask; 1=Pass Note: The working clock of DMA is from AHB1
0x73C HSTIMER_BGR_REG — HSTIMER Bus Gating Reset Register
  [16] HSTIMER_RST — HSTIMER Reset 0: Assert 1: De-assert
    0=Assert; 1=deassert
  [0] HSTIMER_GATING — Gating Clock for HSTIMER 0: Mask 1: Pass Note: The working clock of HSTIMER is from AHB1.
    0=Mask; 1=Pass Note: The working clock of HSTIMER is from AHB1
0x740 AVS_CLK_REG — AVS Clock Register
  [31] SCLK_GATING — Gating Special Clock 0: Clock is OFF 1: Clock is ON SCLK = OSC24M.
    0=OFF (Clock is OFF); 1=ON (Clock is ON SCLK = OSC24M.)
0x78C DBGSYS_BGR_REG — DBGSYS Bus Gating Reset Register
  [16] DBGSYS_RST — DBGSYS Reset 0: Assert 1: De-assert
    0=Assert; 1=deassert
  [0] DBGSYS_GATING — Gating Clock for DBGSYS 0: Mask 1: Pass Note: The working clock of DBGSYS is from OSC24M.
    0=Mask; 1=Pass Note: The working clock of DBGSYS is from OSC24M
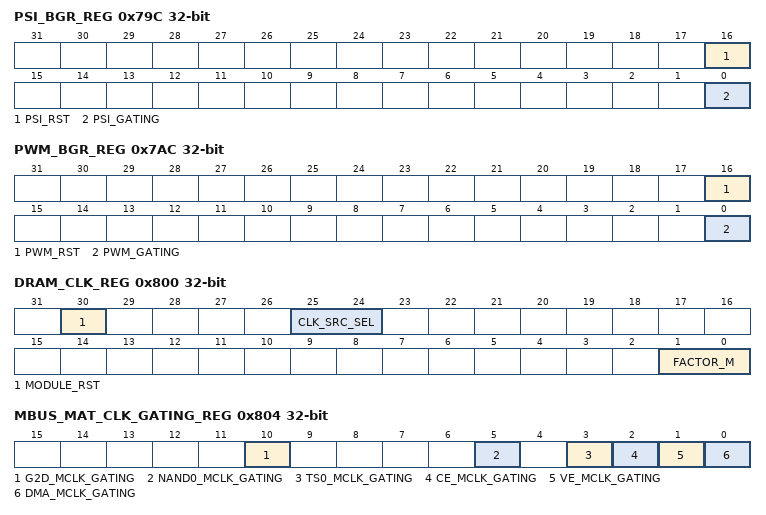
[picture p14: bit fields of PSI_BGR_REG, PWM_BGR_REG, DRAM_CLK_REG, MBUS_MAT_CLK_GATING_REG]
0x79C PSI_BGR_REG — PSI Bus Gating Reset Register
  [16] PSI_RST — PSI Reset 0: Assert 1: De-assert
    0=Assert; 1=deassert
  [0] PSI_GATING — Gating Clock for PSI 0: Mask 1: Pass Note: The working clock of PSI is from PSI clock.
    0=Mask; 1=Pass Note: The working clock of PSI is from PSI clock
0x7AC PWM_BGR_REG — PWM Bus Gating Reset Register
  [16] PWM_RST — PWM Reset 0: Assert 1: De-assert
    0=Assert; 1=deassert
  [0] PWM_GATING — Gating Clock for PWM 0: Mask 1: Pass Note: The working clock of PWM is from APB1 or OSC24M.
    0=Mask; 1=Pass Note: The working clock of PWM is from APB1 or OSC24M
0x7BC IOMMU_BGR_REG — IOMMU Bus Gating Reset Register
  [0] IOMMU_GATING — Gating Clock For IOMMU 0: Mask 1: Pass
    0=Mask; 1=Pass
0x800 DRAM_CLK_REG — DRAM Clock Register
  [30] MODULE_RST — Module Reset 0: Assert 1: De-assert SCLK = Clock Source/M.
    0=Assert; 1=De-assert SCLK = Clock Source/M
  [25:24] CLK_SRC_SEL — Clock Source Select 00: PLL_DDR0 01: PLL_DDR1 1X: /
    0=PLL_DDR0; 1=PLL_DDR1
  [1:0] FACTOR_M — Factor M.(M= FACTOR_M +1) FACTOR_M is from 0 to 3.
0x804 MBUS_MAT_CLK_GATING_REG — MBUS Master Clock Gating Register
  [all] fields
    0=Mask; 1=Pass
  [10] G2D_MCLK_GATING — Gating MBUS Clock For G2D 0: Mask 1: Pass
  [5] NAND0_MCLK_GATING — Gating MBUS Clock For NAND0 0: Mask 1: Pass
  [3] TS0_MCLK_GATING — Gating MBUS Clock For TS0 0: Mask 1: Pass
  [2] CE_MCLK_GATING — Gating MBUS Clock For CE 0: Mask 1: Pass
  [1] VE_MCLK_GATING — Gating MBUS Clock For VE 0: Mask 1: Pass
  [0] DMA_MCLK_GATING — Gating MBUS Clock For DMA 0: Mask 1: Pass
0x80C DRAM_BGR_REG — DRAM Bus Gating Reset Register
  [16] DRAM_RST — DRAM Reset 0: Assert 1: De-assert
    0=Assert; 1=deassert
  [0] DRAM_GATING — Gating Clock for DRAM 0: Mask 1: Pass
    0=Mask; 1=Pass
0x810 NAND0_0_CLK_REG — NAND0_0 Clock Register
  [31] SCLK_GATING — Gating Special Clock 0: Clock is OFF 1: Clock is ON SCLK = Clock Source/M/N.
    values as CE_CLK_REG.SCLK_GATING
  [26:24] CLK_SRC_SEL — Clock Source Select 000: OSC24M 001: PLL_PERI0(1X) 010: PLL_PERI1(1X) 011: PLL_PERI0(2X) 100: PLL_PERI1(2X) 1XX:/
    0=OSC24M; 1=PLL_PERI0_openingparen_1X_closingparen_ (PLL_PERI0(1X)); 2=PLL_PERI1_openingparen_1X_closingparen_ (PLL_PERI1(1X)); 3=PLL_PERI0_openingparen_2X_closingparen_ (PLL_PERI0(2X)); 4=PLL_PERI1_openingparen_2X_closingparen_ (PLL_PERI1(2X) 1XX:/)
  [9:8] FACTOR_N — Factor N 00: 1 01: 2 10: 4 11: 8
    0=_1; 1=_2; 2=_4; 3=_8
  [3:0] FACTOR_M — Factor M.(M= FACTOR_M +1) FACTOR_M is from 0 to 15.
0x814 NAND0_1_CLK_REG — NAND0_1 Clock Register
  [31] SCLK_GATING — Gating Special Clock 0: Clock is OFF 1: Clock is ON SCLK = Clock Source/N/M.
    0=OFF (Clock is OFF); 1=ON (Clock is ON SCLK = Clock Source/N/M.)
  [26:24] CLK_SRC_SEL — Clock Source Select 000: OSC24M 001: PLL_PERI0(1X) 010: PLL_PERI1(1X) 011: PLL_PERI0(2X) 100: PLL_PERI1(2X) 1XX:/
    values as NAND0_0_CLK_REG.CLK_SRC_SEL
  [9:8] FACTOR_N — Factor N 00: 1 01: 2 10: 4 11: 8
    0=_1; 1=_2; 2=_4; 3=_8
  [3:0] FACTOR_M — Factor M.(M= FACTOR_M +1) FACTOR_M is from 0 to 15.
0x82C NAND_BGR_REG — NAND Bus Gating Reset Register
  [16] NAND0_RST — NAND0 Reset 0: Assert 1: De-assert
    0=Assert; 1=deassert
  [0] NAND0_GATING — Gating Clock For NAND0 0: Mask 1: Pass
    0=Mask; 1=Pass
{0x830+4i} SMHC{i}_CLK_REG (i=0..2) — SMHC{i} Clock Register
  [31] SCLK_GATING — Gating Special Clock 0: Clock is OFF 1: Clock is ON SCLK = Clock Source/M/N.
    values as CE_CLK_REG.SCLK_GATING
  [25:24] CLK_SRC_SEL — Clock Source Select 00: OSC24M 01: PLL_PERI0(2X) 10: PLL_PERI1(2X) 11: /
    0=OSC24M; 1=PLL_PERI0_openingparen_2X_closingparen_ (PLL_PERI0(2X)); 2=PLL_PERI1_openingparen_2X_closingparen_ (PLL_PERI1(2X))
  [9:8] FACTOR_N — Factor N 00: 1 01: 2 10: 4 11: 8
    0=_1; 1=_2; 2=_4; 3=_8
  [3:0] FACTOR_M — Factor M.(M= FACTOR_M +1) FACTOR_M is from 0 to 15.
0x84C SMHC_BGR_REG — SMHC Bus Gating Reset Register
  [18] SMHC2_RST — SMHC2 Reset 0: Assert 1: De-assert
    0=Assert; 1=deassert
  [17] SMHC1_RST — SMHC1 Reset 0: Assert 1: De-assert
    0=Assert; 1=deassert
  [16] SMHC0_RST — SMHC0 Reset 0: Assert 1: De-assert
    0=Assert; 1=deassert
  [2] SMHC2_GATING — Gating Clock For SMHC2 0: Mask 1: Pass
    0=Mask; 1=Pass
  [1] SMHC1_GATING — Gating Clock For SMHC1 0: Mask 1: Pass
    0=Mask; 1=Pass
  [0] SMHC0_GATING — Gating Clock For SMHC0 0: Mask 1: Pass
    0=Mask; 1=Pass
0x90C UART_BGR_REG — UART Bus Gating Reset Register
  [n+16] UART{n}_RST (n=0..5) — UART{n} Reset 0: Assert 1: De-assert
    0=Assert; 1=deassert
  [n] UART{n}_GATING (n=0..5) — Gating Clock for UART{n} 0: Mask 1: Pass
    0=Mask; 1=Pass
0x91C TWI_BGR_REG — TWI Bus Gating Reset Register
  [n+16] TWI{n}_RST (n=0..4) — TWI{n} Reset 0: Assert 1: De-assert
    0=Assert; 1=deassert
  [n] TWI{n}_GATING (n=0..4) — Gating Clock for TWI{n} 0: Mask 1: Pass
    0=Mask; 1=Pass
0x940 SPI0_CLK_REG — SPI0 Clock Register
  [31] SCLK_GATING — Gating Special Clock 0: Clock is OFF 1: Clock is ON SCLK = Clock Source/M/N.
    values as CE_CLK_REG.SCLK_GATING
  [26:24] CLK_SRC_SEL — Clock Source Select 000: OSC24M 001: PLL_PERI0(1X) 010: PLL_PERI1(1X) 011: PLL_PERI0(2X) 100: PLL_PERI1(2X) Others: /
    0=OSC24M; 1=PLL_PERI0_openingparen_1X_closingparen_ (PLL_PERI0(1X)); 2=PLL_PERI1_openingparen_1X_closingparen_ (PLL_PERI1(1X)); 3=PLL_PERI0_openingparen_2X_closingparen_ (PLL_PERI0(2X)); 4=PLL_PERI1_openingparen_2X_closingparen_ (PLL_PERI1(2X) Others: /)
  [9:8] FACTOR_N — Factor N 00: 1 01: 2 10: 4 11: 8
    0=_1; 1=_2; 2=_4; 3=_8
  [3:0] FACTOR_M — Factor M.(M= FACTOR_M +1) FACTOR_M is from 0 to 15.
0x944 SPI1_CLK_REG — SPI1 Clock Register
  fields as SPI0_CLK_REG
0x96C SPI_BGR_REG — SPI Bus Gating Reset Register
  [17] SPI1_RST — SPI1 Reset 0: Assert 1: De-assert
    0=Assert; 1=deassert
  [16] SPI0_RST — SPI0 Reset 0: Assert 1: De-assert
    0=Assert; 1=deassert
  [1] SPI1_GATING — Gating Clock for SPI1 0: Mask 1: Pass
    0=Mask; 1=Pass
  [0] SPI0_GATING — Gating Clock for SPI0 0: Mask 1: Pass
    0=Mask; 1=Pass
0x970 EPHY_25M_CLK_REG — EPHY_25M Clock Register
  [31] SCLK_GATING — Gating Special Clock 0: Clock is OFF 1: Clock is ON SCLK = PLL_PERI0(1X)/24 = 25M.
    0=OFF (Clock is OFF); 1=ON (Clock is ON SCLK = PLL_PERI0(1X)/24 = 25M.)
  [30] PLL_PERI0_GATING — Gating PLL_PERI0 Clock 0: Clock is OFF 1: Clock is ON
    0=OFF (Clock is OFF); 1=ON (Clock is ON)
0x97C EMAC_BGR_REG — EMAC Bus Gating Reset Register
  [17] EMAC1_RST — EMAC1 Reset 0: Assert 1: De-assert
    0=Assert; 1=deassert
  [16] EMAC0_RST — EMAC0 Reset 0: Assert 1: De-assert
    0=Assert; 1=deassert
  [1] EMAC1_GATING — Gating Clock for EMAC1 0: Mask 1: Pass
    0=Mask; 1=Pass
  [0] EMAC0_GATING — Gating Clock for EMAC0 0: Mask 1: Pass
    0=Mask; 1=Pass
0x9B0 TS_CLK_REG — TS Clock Register
  [31] SCLK_GATING — Gating Special Clock 0: Clock is OFF 1: Clock is ON SCLK = Clock Source/M/N.
    values as CE_CLK_REG.SCLK_GATING
  [24] CLK_SRC_SEL — Clock Source Select 0: OSC24M 1: PLL_PERI0(1X)
    0=OSC24M; 1=PLL_PERI0_openingparen_1X_closingparen_ (PLL_PERI0(1X))
  [9:8] FACTOR_N — Factor N 00: 1 01: 2 10: 4 11: 8
    0=_1; 1=_2; 2=_4; 3=_8
  [3:0] FACTOR_M — Factor M.(M= FACTOR_M +1) FACTOR_M is from 0 to 15.
0x9BC TS_BGR_REG — TS Bus Gating Reset Register
  [16] TS_RST — TS Reset 0: Assert 1: De-assert
    0=Assert; 1=deassert
  [0] TS_GATING — Gating Clock For TS 0: Mask 1: Pass
    0=Mask; 1=Pass
0x9FC THS_BGR_REG — THS Bus Gating Reset Register
  [16] THS_RST — THS Reset 0: Assert 1: De-assert
    0=Assert; 1=deassert
  [0] THS_GATING — Gating Clock for THS 0: Mask 1: Pass Note: The working clock of THS is from OSC24M.
    0=Mask; 1=Pass Note: The working clock of THS is from OSC24M
0xA20 OWA_CLK_REG — OWA Clock Register
  [31] SCLK_GATING — Gating Special Clock 0: Clock is OFF 1: Clock is ON SCLK = Clock Source/N
    0=OFF (Clock is OFF); 1=ON (Clock is ON SCLK = Clock Source/N)
  [25:24] CLK_SRC_SEL — Clock Source Select 00: PLL_AUDIO(1X) 01: PLL_AUDIO(2X) 10: PLL_AUDIO(4X) 11: PLL_AUDIO(hs)
    0=PLL_AUDIO_openingparen_1X_closingparen_ (PLL_AUDIO(1X)); 1=PLL_AUDIO_openingparen_2X_closingparen_ (PLL_AUDIO(2X)); 2=PLL_AUDIO_openingparen_4X_closingparen_ (PLL_AUDIO(4X)); 3=PLL_AUDIO_openingparen_hs_closingparen_ (PLL_AUDIO(hs))
  [9:8] FACTOR_N — Factor N 00: 1 01: 2 10: 4 11: 8
    0=_1; 1=_2; 2=_4; 3=_8
0xA2C OWA_BGR_REG — OWA Bus Gating Reset Register
  [16] OWA_RST — OWA Reset 0: Assert 1: De-assert
    0=Assert; 1=deassert
  [0] OWA_GATING — Gating Clock For OWA 0: Mask 1: Pass
    0=Mask; 1=Pass
0xA40 DMIC_CLK_REG — DMIC Clock Register
  fields as OWA_CLK_REG
0xA4C DMIC_BGR_REG — DMIC Bus Gating Reset Register
  [16] DMIC_RST — DMIC Reset 0: Assert 1: De-assert
    0=Assert; 1=deassert
  [0] DMIC_GATING — Gating Clock For DMIC 0: Mask 1: Pass
    0=Mask; 1=Pass
0xA50 AUDIO_CODEC_1X_CLK_REG — AUDIO CODEC 1X Clock Register
  [31] SCLK_GATING — Gating Special Clock 0: Clock is OFF 1: Clock is ON SCLK = Clock Source/M.
    values as DE_CLK_REG.SCLK_GATING
  [25:24] CLK_SRC_SEL — Clock Source Select 00: PLL_AUDIO(1X) 01: PLL_AUDIO(2X) 10: PLL_AUDIO(4X) 11: PLL_AUDIO(hs)
    values as OWA_CLK_REG.CLK_SRC_SEL
  [3:0] FACTOR_M — Factor M.(M= FACTOR_M +1) FACTOR_M is from 0 to 15.
0xA54 AUDIO_CODEC_4X_CLK_REG — AUDIO CODEC 4X Clock Register
  fields as AUDIO_CODEC_1X_CLK_REG
0xA5C AUDIO_CODEC_BGR_REG — AUDIO CODEC Bus Gating Reset Register
  [16] AUDIO_CODEC_RST — AUDIO_CODEC Reset 0: Assert 1: De-assert
    0=Assert; 1=deassert
  [0] AUDIO_CODEC_GATING — Gating Clock For AUDIO_CODEC 0: Mask 1: Pass
    0=Mask; 1=Pass
0xA60 AUDIO_HUB_CLK_REG — AUDIO_HUB Clock Register
  [31] SCLK_GATING — Gating Special Clock 0: Clock is OFF 1: Clock is ON SCLK = Clock Source/N.
    0=OFF (Clock is OFF); 1=ON (Clock is ON SCLK = Clock Source/N.)
  [25:24] CLK_SRC_SEL — Clock Source Select 00: PLL_AUDIO(1X) 01: PLL_AUDIO(2X) 10: PLL_AUDIO(4X) 11: PLL_AUDIO(hs)
    values as OWA_CLK_REG.CLK_SRC_SEL
  [9:8] FACTOR_N — Factor N 00: 1 01: 2 10: 4 11: 8
    0=_1; 1=_2; 2=_4; 3=_8
0xA6C AUDIO_HUB_BGR_REG — AUDIO_HUB Bus Gating Reset Register
  [16] AUDIO_HUB_RST — AUDIO_HUB Reset 0: Assert 1: De-assert
    0=Assert; 1=deassert
  [0] AUDIO_HUB_GATING — Gating Clock For AUDIO_HUB 0: Mask 1: Pass
    0=Mask; 1=Pass
{0xA70+4i} USB{i}_CLK_REG (i=0..2) — USB{i} Clock Register
  [31] SCLK_GATING_OHCI{i} — Gating Special Clock For OHCI{i} 0: Clock is OFF 1: Clock is ON
    0=OFF (Clock is OFF); 1=ON (Clock is ON)
  [30] USBPHY{i}_RST — USB PHY{i} Reset 0: Assert 1: De-assert
    0=Assert; 1=deassert
  [29] SCLK_GATING_USBPHY{i} — Gating Special Clock For USBPHY{i} 0: Clock is OFF 1: Clock is ON SCLK is from OSC24M.
    0=OFF (Clock is OFF); 1=ON (Clock is ON SCLK is from OSC24M.)
  [25:24] OHCI{i}_12M_SRC_SEL — OHCI{i} 12M Source Select 00: 12M divided from 48 MHz 01: 12M divided from 24 MHz 10: LOSC 11: /
0xA7C USB3_CLK_REG
  [31] SCLK_GATING_OHCI3 — Gating Special Clock For OHCI3 0: Clock is OFF 1: Clock is ON
    0=OFF (Clock is OFF); 1=ON (Clock is ON)
  [30] USBPHY3_RST — USB PHY3 Reset 0: Assert 1: De-assert
    0=Assert; 1=deassert
  [29] SCLK_GATING_USBPHY3 — Gating Special Clock For USBPHY3 0: Clock is OFF 1: Clock is ON SCLK is from OSC24M.
    values as USB0_CLK_REG.SCLK_GATING_USBPHY{i}
  [25:24] OHCI3_12M_SRC_SEL — OHCI3 12M Source Select 00: 12M divided from 48 MHz 01: 12M divided from 24 MHz 10: LOSC 11: /
0xA8C USB_BGR_REG — USB Bus Gating Reset Register
  [24] USBOTG_RST — USBOTG Reset 0: Assert 1: De-assert
    0=Assert; 1=deassert
  [n+20] USBEHCI{n}_RST (n=0..3) — USBEHCI{n} Reset 0: Assert 1: De-assert
    0=Assert; 1=deassert
  [19] USBOHCI3_RST — USBOHCI3 Reset. 0: Assert 1: De-assert
    0=Assert; 1=deassert
  [18] USBOHCI2_RST — USBOHCI2 Reset. 0: Assert 1: De-assert
    0=Assert; 1=deassert
  [17] USBOHCI1_RST — USBOHCI1 Reset. 0: Assert 1: De-assert
    0=Assert; 1=deassert
  [16] USBOHCI0_RST — USBOHCI0 Reset 0: Assert 1: De-assert
    0=Assert; 1=deassert
  [8] USBOTG_GATING — Gating Clock For USBOTG 0: Mask 1: Pass
    0=Mask; 1=Pass
  [n+4] USBEHCI{n}_GATING (n=0..3) — Gating Clock For USBEHCI{n} 0: Mask 1: Pass
    0=Mask; 1=Pass
  [n] USBOHCI{n}_GATING (n=0..3) — Gating Clock For USBOHCI{n} 0: Mask 1: Pass
    0=Mask; 1=Pass
0xA9C LRADC_BGR_REG
  [16] LRADC_RST — LRADC Reset 0: Assert 1: De-assert
    0=Assert; 1=deassert
  [0] LRADC_GATING — Gating Clock For LRADC 0: Mask 1: Pass
    0=Mask; 1=Pass
0xB00 HDMI0_CLK_REG — HDMI0 Clock Register
  [31] SCLK_GATING — Gating Special Clock 0: Clock is OFF 1: Clock is ON SCLK = Clock Source/M.
    values as DE_CLK_REG.SCLK_GATING
  [25:24] CLK_SRC_SEL — Clock Source Select 00: PLL_VIDEO0(1X) 01: PLL_VIDEO0(4X) 10:PLL_VIDEO2(1X) 11:PLL_VIDEO2(4X)
    0=PLL_VIDEO0_openingparen_1X_closingparen_ (PLL_VIDEO0(1X)); 1=PLL_VIDEO0_openingparen_4X_closingparen_ (PLL_VIDEO0(4X) 10:PLL_VIDEO2(1X) 11:PLL_VIDEO2(4X))
  [3:0] FACTOR_M — Factor M.(M= FACTOR_M +1) FACTOR_M is from 0 to 15.
0xB04 HDMI0_SLOW_CLK_REG — HDMI0 Slow Clock Register
  fields as AVS_CLK_REG
0xB10 HDMI_CEC_CLK_REG — HDMI CEC Clock Register
  [31] SCLK_GATING — Gating Special Clock 0: Clock is OFF 1: Clock is ON
    0=OFF (Clock is OFF); 1=ON (Clock is ON)
  [30] PLL_PERI_GATING — Gating PLL_PERI Clock 0:Clock is OFF 1:Clock is ON
  [25:24] CLK_SRC_SEL — Clock Source Select 00: CCMU_32K 01: PLL_PERI0(2X)/36621 = 32.768kHz 1X:/
    0=CCMU_32K; 1=PLL_PERI0_openingparen_2X_closingparen__slash_36621 (PLL_PERI0(2X)/36621 = 32.768kHz 1X:/)
0xB1C HDMI_BGR_REG — HDMI Bus Gating Reset Register
  [17] HDMI0_SUB_RST — HDMI0_SUB Reset 0: Assert 1: De-assert
    0=Assert; 1=deassert
  [16] HDMI0_MAIN_RST — HDMI0_MAIN Reset 0: Assert 1: De-assert
    0=Assert; 1=deassert
  [0] HDMI0_GATING — Gating Clock For HDMI0 0: Mask 1: Pass
    0=Mask; 1=Pass
0xB5C DISPLAY_IF_TOP_BGR_REG — DISPLAY_IF_TOP BUS GATING RESET Register
  [16] DISPLAY_IF_TOP_RST — DISPLAY_IF_TOP Reset 0: Assert 1: De-assert
    0=Assert; 1=deassert
  [0] DISPLAY_IF_TOP_GATING — Gating Clock For DISPLAY_IF_TOP 0: Mask 1: Pass
    0=Mask; 1=Pass
0xB80 TCON_TV0_CLK_REG — TCON TV0 Clock Register
  [31] SCLK_GATING — Gating Special Clock 0: Clock is OFF 1: Clock is ON SCLK = Clock Source/M/N.
    values as CE_CLK_REG.SCLK_GATING
  [26:24] CLK_SRC_SEL — Clock Source Select 000: PLL_VIDEO0(1X) 001: PLL_VIDEO0(4X) 010: PLL_VIDEO1(1X) 011: PLL_VIDEO1(4X) 100: / 101: /
    0=PLL_VIDEO0_openingparen_1X_closingparen_ (PLL_VIDEO0(1X)); 1=PLL_VIDEO0_openingparen_4X_closingparen_ (PLL_VIDEO0(4X)); 2=PLL_VIDEO1_openingparen_1X_closingparen_ (PLL_VIDEO1(1X)); 3=PLL_VIDEO1_openingparen_4X_closingparen_ (PLL_VIDEO1(4X))
  [9:8] FACTOR_N — Factor N 00: 1 01: 2 10: 4 11: 8
    0=_1; 1=_2; 2=_4; 3=_8
  [3:0] FACTOR_M — Factor M.(M= FACTOR_M +1) FACTOR_M is from 0 to 15.
0xB84 TCON_TV1_CLK_REG — TCON TV1 Clock Register
  fields as TCON_TV0_CLK_REG
0xB9C TCON_TV_BGR_REG — TCON TV GATING RESET Register
  [17] TCON_TV1_RST — TCON_TV1 Reset 0: Assert 1: De-assert
    0=Assert; 1=deassert
  [16] TCON_TV0_RST — TCON_TV0 Reset 0: Assert 1: De-assert
    0=Assert; 1=deassert
  [1] TCON_TV1_GATING — Gating Clock For TCON_TV1 0: Mask 1: Pass
    0=Mask; 1=Pass
  [0] TCON_TV0_GATING — Gating Clock For TCON_TV0 0: Mask 1: Pass
    0=Mask; 1=Pass
0xBB0 TVE0_CLK_REG — TVE0 Clock Register
  fields as TCON_TV0_CLK_REG
0xBBC TVE_BGR_REG — TVE BUS GATING RESET Register
  [17] TVE0_RST — TVE0 Reset 0: Assert 1: De-assert
    0=Assert; 1=deassert
  [16] TVE_TOP_RST — TVE_TOP Reset 0: Assert 1: De-assert
    0=Assert; 1=deassert
  [1] TVE0_GATING — Gating Clock For TVE0 0: Mask 1: Pass
    0=Mask; 1=Pass
  [0] TVE_TOP_GATING — Gating Clock For TCON_TV1 0: Mask 1: Pass
    0=Mask; 1=Pass
0xC40 HDMI_HDCP_CLK_REG — HDMI HDCP Clock Register
  [31] SCLK_GATING — Gating Special Clock 0: Clock is OFF 1: Clock is ON SCLK = Clock Source/M.
    values as DE_CLK_REG.SCLK_GATING
  [25:24] CLK_SRC_SEL — Clock Source Select 00: PLL_PERI0(1X) 01: PLL_PERI1(1X) Others:/
    0=PLL_PERI0_openingparen_1X_closingparen_ (PLL_PERI0(1X)); 1=PLL_PERI1_openingparen_1X_closingparen_ (PLL_PERI1(1X) Others:/)
  [3:0] FACTOR_M — Factor M.(M= FACTOR_M +1) FACTOR_M is from 0 to 15.
0xC4C HDMI_HDCP_BGR_REG — HDMI HDCP Bus Gating Reset Register
  [16] HDMI_HDCP_RST — HDMI_HDCP Reset 0: Assert 1: De-assert
    0=Assert; 1=deassert
  [0] HDMI_HDCP_GATING — Gating Clock For HDMI_HDCP 0: Mask 1: Pass
    0=Mask; 1=Pass
0xF00 CCMU_SEC_SWITCH_REG
  [all] fields
    0=Secure; 1=non_secure
  [2] MBUS_SEC — MBUS clock registers` security 0: Secure 1: Non-secure
  [1] BUS_SEC — Bus relevant registers' security 0: Secure 1: Non-secure
  [0] PLL_SEC — PLL relevant registers' security 0: Secure 1: Non-secure
0xF04 PLL_LOCK_DBG_CTRL_REG — PLL Lock Debug Control Register
  [31] DBG_EN — Debug Enable 0: Disable 1: Enable
    0=Disable; 1=Enable
  [24:20] DBG_SEL — Debug Select 00000: PLL_C0_CPUX 00001: / 00010: PLL_DDR0 00011: PLL_DDR1 00100: PLL_PERI0 00101: PLL_PERI1 00110: PLL_GPU 00111: / 01000: PLL_VIDEO0 01001: PLL_VIDEO1 01010: / 01011: PLL_VE 01100: PLL_DE 01101: / 01110: / 01111: PLL_AUDIO 10000: / 10001: / 10010: / 10011: / 10100: / 10101: / 10110: / 10111: / 11000: / 11001: / 11010: / 11011: / 11100: / Others: /
    0=PLL_C0_CPUX; 2=PLL_DDR0; 3=PLL_DDR1; 4=PLL_PERI0; 5=PLL_PERI1; 6=PLL_GPU; 8=PLL_VIDEO0; 9=PLL_VIDEO1; 11=PLL_VE; 12=PLL_DE; 15=PLL_AUDIO; 28=_slash_ (/ Others: /)
  [18:17] UNLOCK_LEVEL — Unlock Level 00: 21-29 Clock Cycles 01: 22-28 Clock Cycles 1X: 20-30 Clock Cycles
    0=_21_minus_29 (21-29 Clock Cycles); 1=_22_minus_28 (22-28 Clock Cycles); 2=_20_minus_30 (20-30 Clock Cycles)
  [16] LOCK_LEVEL — Lock Level 0: 24-26 Clock Cycles 1: 23-27 Clock Cycles
    0=_24_minus_26 (24-26 Clock Cycles); 1=_23_minus_27 (23-27 Clock Cycles)
0xF08 FRE_DET_CTRL_REG reset 0x20 — Frequency Detect Control Register
  [31] ERROR_FLAG_ERROR — ERROR_FLAG Error Flag 0: Write 0 to clear 1: Error
    0=Write 0 to clear; 1=Error
  [8:4] DETECT_TIME — Detect Time Time=1/32k*(2^RegValue) Note: RegValue is from 0 to 16.
  [1] FRE_DET_IRQ_EN_FREQUENCE — FRE_DET_IRQ_EN Frequence Detect IRQ Enable 0: Disable 1: Enable
    0=Disable; 1=Enable
  [0] FRE_DET_FUN_EN_FREQUENCE — FRE_DET_FUN_EN Frequence Detect Function Enable 0: Disable 1: Enable
    0=Disable; 1=Enable
0xF0C FRE_UP_LIM_REG — Frequency Up Limit Register
  [31:0] FRE_UP_LIM — Frequence Up Limit The register must be an integral multiple of 32. The unit is kHz.
0xF10 FRE_DOWN_LIM_REG — Frequency Down Limit Register
  [31:0] FRE_DOWN_LIM — Frequence Down Limit The register must be an integral multiple of 32. The unit is kHz.
0xF20 _24M_27M_CLK_OUTPUT_REG
  [1:0] DIV_SEL — 00:Div2 01:Div4 10:Div8 11:Div16 Only for 27M clock.
